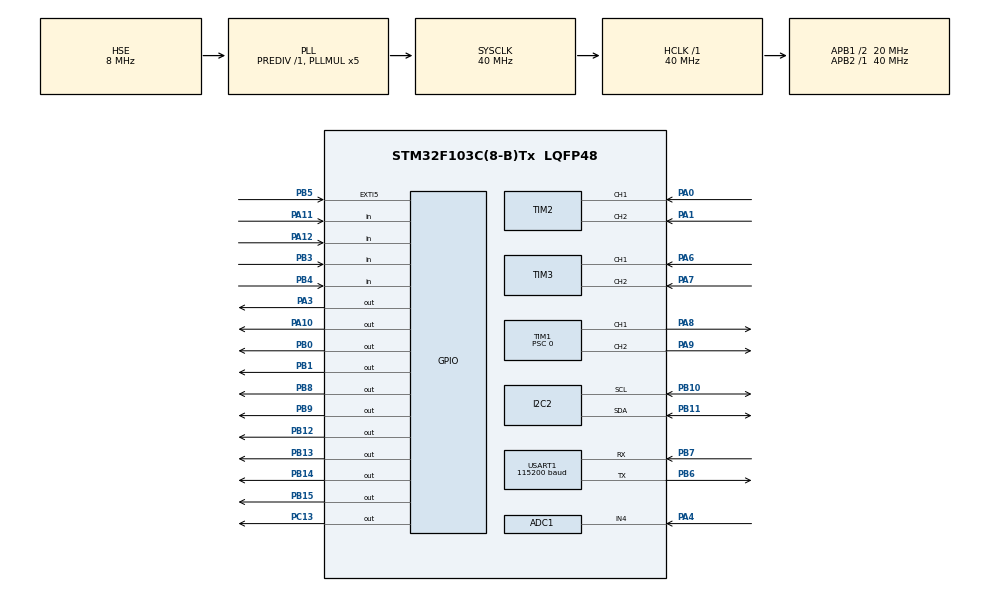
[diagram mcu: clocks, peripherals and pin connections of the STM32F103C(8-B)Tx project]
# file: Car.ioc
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Mcu.Family=STM32F1
Mcu.Name=STM32F103C(8-B)Tx
Mcu.Package=LQFP48
NVIC.EXTI9_5_IRQn=true\:0\:0\:false\:false\:true\:true\:true\:true
NVIC.PriorityGroup=NVIC_PRIORITYGROUP_4
NVIC.TIM4_IRQn=true\:0\:0\:false\:false\:true\:true\:true\:true
NVIC.USART1_IRQn=true\:0\:0\:false\:false\:true\:true\:true\:true
PA0-WKUP.Signal=S_TIM2_CH1_ETR
PA1.Signal=S_TIM2_CH2
PA10.GPIO_PuPd=GPIO_PULLUP
PA10.PinState=GPIO_PIN_SET
PA10.Signal=GPIO_Output
PA11.GPIO_Mode=GPIO_MODE_INPUT
PA11.GPIO_PuPd=GPIO_NOPULL
PA11.Signal=GPIO_Input
PA12.GPIO_Mode=GPIO_MODE_INPUT
PA12.GPIO_PuPd=GPIO_NOPULL
PA12.Signal=GPIO_Input
PA13.Mode=Serial_Wire
PA13.Signal=SYS_JTMS-SWDIO
PA14.Mode=Serial_Wire
PA14.Signal=SYS_JTCK-SWCLK
PA3.Signal=GPIO_Output
PA4.Signal=ADCx_IN4
PA6.Signal=S_TIM3_CH1
PA7.Signal=S_TIM3_CH2
PA8.Signal=S_TIM1_CH1
PA9.Signal=S_TIM1_CH2
PB10.Mode=I2C
PB10.Signal=I2C2_SCL
PB11.Mode=I2C
PB11.Signal=I2C2_SDA
PB12.GPIO_ModeDefaultOutputPP=GPIO_MODE_OUTPUT_PP
PB12.GPIO_PuPd=GPIO_PULLUP
PB12.GPIO_Speed=GPIO_SPEED_FREQ_LOW
PB12.PinState=GPIO_PIN_RESET
PB12.Signal=GPIO_Output
PB13.GPIO_ModeDefaultOutputPP=GPIO_MODE_OUTPUT_PP
PB13.GPIO_PuPd=GPIO_PULLUP
PB13.GPIO_Speed=GPIO_SPEED_FREQ_LOW
PB13.PinState=GPIO_PIN_RESET
PB13.Signal=GPIO_Output
PB14.GPIO_ModeDefaultOutputPP=GPIO_MODE_OUTPUT_PP
PB14.GPIO_PuPd=GPIO_PULLUP
PB14.GPIO_Speed=GPIO_SPEED_FREQ_LOW
PB14.PinState=GPIO_PIN_RESET
PB14.Signal=GPIO_Output
PB15.GPIO_ModeDefaultOutputPP=GPIO_MODE_OUTPUT_PP
PB15.GPIO_PuPd=GPIO_PULLUP
PB15.GPIO_Speed=GPIO_SPEED_FREQ_LOW
PB15.PinState=GPIO_PIN_RESET
PB15.Signal=GPIO_Output
PB3.GPIO_Mode=GPIO_MODE_INPUT
PB3.GPIO_PuPd=GPIO_NOPULL
PB3.Signal=GPIO_Input
PB4.GPIO_Mode=GPIO_MODE_INPUT
PB4.GPIO_PuPd=GPIO_NOPULL
PB4.Signal=GPIO_Input
PB5.Signal=GPXTI5
PB6.Mode=Asynchronous
PB6.Signal=USART1_TX
PB7.Mode=Asynchronous
PB7.Signal=USART1_RX
PB8.GPIO_ModeDefaultOutputPP=GPIO_MODE_OUTPUT_OD
PB8.GPIO_PuPd=GPIO_NOPULL
PB8.GPIO_Speed=GPIO_SPEED_FREQ_HIGH
PB8.PinState=GPIO_PIN_RESET
PB8.Signal=GPIO_Output
PB9.GPIO_ModeDefaultOutputPP=GPIO_MODE_OUTPUT_OD
PB9.GPIO_PuPd=GPIO_NOPULL
PB9.GPIO_Speed=GPIO_SPEED_FREQ_HIGH
PB9.PinState=GPIO_PIN_RESET
PB9.Signal=GPIO_Output
PC13-TAMPER-RTC.GPIO_ModeDefaultOutputPP=GPIO_MODE_OUTPUT_PP
PC13-TAMPER-RTC.GPIO_PuPd=GPIO_NOPULL
PC13-TAMPER-RTC.Signal=GPIO_Output
PD0-OSC_IN.Mode=HSE-External-Oscillator
PD0-OSC_IN.Signal=RCC_OSC_IN
PD1-OSC_OUT.Mode=HSE-External-Oscillator
PD1-OSC_OUT.Signal=RCC_OSC_OUT
ProjectManager.HeapSize=0x200
ProjectManager.StackSize=0x400
ProjectManager.TargetToolchain=MDK-ARM V5.32
RCC.AHBFreq_Value=40000000
RCC.APB1CLKDivider=RCC_HCLK_DIV2
RCC.APB1Freq_Value=20000000
RCC.APB1TimFreq_Value=40000000
RCC.APB2Freq_Value=40000000
RCC.APB2TimFreq_Value=40000000
RCC.HCLKFreq_Value=40000000
RCC.PLLMUL=RCC_PLL_MUL5
RCC.PLLSourceVirtual=RCC_PLLSOURCE_HSE
RCC.SYSCLKFreq_VALUE=40000000
RCC.SYSCLKSource=RCC_SYSCLKSOURCE_PLLCLK
RCC.USBFreq_Value=40000000
SH.S_TIM1_CH1.0=TIM1_CH1,PWM Generation1 CH1
SH.S_TIM1_CH2.0=TIM1_CH2,PWM Generation2 CH2
SH.S_TIM2_CH1_ETR.0=TIM2_CH1,Encoder_Interface
SH.S_TIM2_CH2.0=TIM2_CH2,Encoder_Interface
SH.S_TIM3_CH1.0=TIM3_CH1,Encoder_Interface
SH.S_TIM3_CH2.0=TIM3_CH2,Encoder_Interface
TIM1.AutoReloadPreload=TIM_AUTORELOAD_PRELOAD_ENABLE
TIM1.Channel-PWM\ Generation1\ CH1=TIM_CHANNEL_1
TIM1.Channel-PWM\ Generation2\ CH2=TIM_CHANNEL_2
TIM1.OC1Preload_PWM=DISABLE
TIM1.Period=40000-1
TIM1.Prescaler=0
TIM1.Pulse-PWM\ Generation1\ CH1=500
TIM1.Pulse-PWM\ Generation2\ CH2=500
TIM2.EncoderMode=TIM_ENCODERMODE_TI12
TIM2.IC1Polarity=TIM_ICPOLARITY_RISING
TIM3.EncoderMode=TIM_ENCODERMODE_TI12
TIM4.AutoReloadPreload=TIM_AUTORELOAD_PRELOAD_ENABLE
TIM4.Period=5000-1
TIM4.Prescaler=80-1
USART1.BaudRate=115200
USART1.VirtualMode=VM_ASYNC
VP_TIM1_VS_ClockSourceINT.Mode=Internal
VP_TIM4_VS_ClockSourceINT.Mode=Internal
board=custom
ADC1.Channel-4#ChannelRegularConversion=ADC_CHANNEL_4
ADC1.NbrOfConversionFlag=1
ADC1.Rank-4#ChannelRegularConversion=1
ADC1.SamplingTime-4#ChannelRegularConversion=ADC_SAMPLETIME_55CYCLES_5
ADC1.master=1
PB0.GPIO_ModeDefaultOutputPP=GPIO_MODE_OUTPUT_PP
PB0.GPIO_PuPd=GPIO_NOPULL
PB0.GPIO_Speed=GPIO_SPEED_FREQ_LOW
PB0.PinState=GPIO_PIN_RESET
PB0.Signal=GPIO_Output
PB1.GPIO_ModeDefaultOutputPP=GPIO_MODE_OUTPUT_PP
PB1.GPIO_PuPd=GPIO_NOPULL
PB1.GPIO_Speed=GPIO_SPEED_FREQ_LOW
PB1.PinState=GPIO_PIN_RESET
PB1.Signal=GPIO_Output
RCC.ADCPresc=RCC_ADCPCLK2_DIV6
SH.ADCx_IN4.0=ADC1_IN4,IN4

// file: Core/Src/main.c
/* USER CODE BEGIN Header */
/**
  ******************************************************************************
  * @file           : main.c
  * @brief          : Main program body
  ******************************************************************************
  * @attention
  *
  * Copyright (c) 2026 STMicroelectronics.
  * All rights reserved.
  *
  * This software is licensed under terms that can be found in the LICENSE file
  * in the root directory of this software component.
  * If no LICENSE file comes with this software, it is provided AS-IS.
  *
  ******************************************************************************
  */
/* USER CODE END Header */
#include "main.h"
#include "i2c.h"
#include "tim.h"
#include "usart.h"
#include "adc.h"
#include "gpio.h"

/* USER CODE BEGIN Includes */
#include "main.h"
/* USER CODE END Includes */

void SystemClock_Config(void);

int main(void)
{

  /* MCU Configuration--------------------------------------------------------*/

  /* Reset of all peripherals, Initializes the Flash interface and the Systick. */
  HAL_Init();

  /* Configure the system clock */
  SystemClock_Config();

  /* Initialize all configured peripherals */
  MX_GPIO_Init();
  MX_TIM1_Init();
  MX_TIM2_Init();
  MX_TIM3_Init();
  MX_TIM4_Init();
  MX_I2C2_Init();
  MX_USART1_UART_Init();
  MX_ADC1_Init();
  /* USER CODE BEGIN 2 */
  setup();
  /* USER CODE END 2 */

  /* Infinite loop */
  /* USER CODE BEGIN WHILE */
  while (1)
  {
		loop();
    /* USER CODE END WHILE */

  }
}

void SystemClock_Config(void)
{
  RCC_OscInitTypeDef RCC_OscInitStruct = {0};
  RCC_ClkInitTypeDef RCC_ClkInitStruct = {0};
  RCC_PeriphCLKInitTypeDef PeriphClkInit = {0};

  /** Initializes the RCC Oscillators according to the specified parameters
  * in the RCC_OscInitTypeDef structure.
  */
  RCC_OscInitStruct.OscillatorType = RCC_OSCILLATORTYPE_HSE;
  RCC_OscInitStruct.HSEState = RCC_HSE_ON;
  RCC_OscInitStruct.HSEPredivValue = RCC_HSE_PREDIV_DIV1;
  RCC_OscInitStruct.HSIState = RCC_HSI_ON;
  RCC_OscInitStruct.PLL.PLLState = RCC_PLL_ON;
  RCC_OscInitStruct.PLL.PLLSource = RCC_PLLSOURCE_HSE;
  RCC_OscInitStruct.PLL.PLLMUL = RCC_PLL_MUL5;
  if (HAL_RCC_OscConfig(&RCC_OscInitStruct) != HAL_OK)
  {
    Error_Handler();
  }

  /** Initializes the CPU, AHB and APB buses clocks
  */
  RCC_ClkInitStruct.ClockType = RCC_CLOCKTYPE_HCLK|RCC_CLOCKTYPE_SYSCLK
                              |RCC_CLOCKTYPE_PCLK1|RCC_CLOCKTYPE_PCLK2;
  RCC_ClkInitStruct.SYSCLKSource = RCC_SYSCLKSOURCE_PLLCLK;
  RCC_ClkInitStruct.AHBCLKDivider = RCC_SYSCLK_DIV1;
  RCC_ClkInitStruct.APB1CLKDivider = RCC_HCLK_DIV2;
  RCC_ClkInitStruct.APB2CLKDivider = RCC_HCLK_DIV1;

  if (HAL_RCC_ClockConfig(&RCC_ClkInitStruct, FLASH_LATENCY_1) != HAL_OK)
  {
    Error_Handler();
  }

  PeriphClkInit.PeriphClockSelection = RCC_PERIPHCLK_ADC;
  PeriphClkInit.AdcClockSelection = RCC_ADCPCLK2_DIV6;
  if (HAL_RCCEx_PeriphCLKConfig(&PeriphClkInit) != HAL_OK)
  {
    Error_Handler();
  }
}

void Error_Handler(void)
{
  __disable_irq();
  while (1)
  {
  }
}
